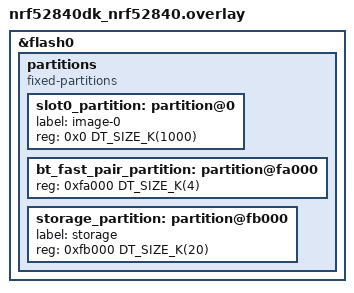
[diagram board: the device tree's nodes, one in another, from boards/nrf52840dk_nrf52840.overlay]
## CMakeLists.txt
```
#
# Copyright (c) 2022 Nordic Semiconductor
#
# SPDX-License-Identifier: LicenseRef-Nordic-5-Clause
#
cmake_minimum_required(VERSION 3.20.0)

find_package(Zephyr REQUIRED HINTS $ENV{ZEPHYR_BASE})
project(input_device)

# NORDIC SDK APP START
target_sources(app PRIVATE
  src/main.c
  src/bt_adv_helper.c
  src/hids_helper.c
  src/bt_le_adv_prov_uuid16.c
  src/battery_module.c
)

target_include_directories(app PRIVATE include)
# NORDIC SDK APP END
```

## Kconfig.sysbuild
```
#
# Copyright (c) 2023-2025 Nordic Semiconductor
#
# SPDX-License-Identifier: LicenseRef-Nordic-5-Clause
#

config BT_FAST_PAIR_MODEL_ID
	default 0x2A410B

# The Anti-Spoofing Private Key is confidential and must be handled securely.
# The following key is only used for demonstration purposes and must not be used in production.
config BT_FAST_PAIR_ANTI_SPOOFING_PRIVATE_KEY
	default "Unoh+nycK/ZJ7k3dHsdcNpiP1SfOy0P/Lx5XixyYois="

source "share/sysbuild/Kconfig"
```

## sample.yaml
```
sample:
  name: Fast Pair input device
  description: Bluetooth Fast Pair Provider sample setup for the input device use
    case
tests:
  sample.bluetooth.fast_pair.input_device:
    build_only: true
    sysbuild: true
    integration_platforms:
      - nrf54l15dk/nrf54l05/cpuapp
      - nrf54lm20dk/nrf54lm20a/cpuapp
      - nrf54lm20dk/nrf54lm20b/cpuapp
      - nrf54ls05dk/nrf54ls05a/cpuapp
      - nrf54lc10dk/nrf54lc10a/cpuapp
    platform_allow:
      - nrf54l15dk/nrf54l05/cpuapp
      - nrf54l15dk/nrf54l10/cpuapp
      - nrf54l15dk/nrf54l15/cpuapp
      - nrf54lm20dk/nrf54lm20a/cpuapp
      - nrf54lm20dk/nrf54lm20b/cpuapp
      - nrf54ls05dk/nrf54ls05a/cpuapp
      - nrf54ls05dk/nrf54ls05b/cpuapp
      - nrf54lc10dk/nrf54lc10a/cpuapp
      - nrf54lc10dk/nrf54lc10a/cpuapp/ns
    tags:
      - bluetooth
      - ci_build
      - sysbuild
      - ci_samples_bluetooth
```

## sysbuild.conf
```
#
# Copyright (c) 2023 Nordic Semiconductor
#
# SPDX-License-Identifier: LicenseRef-Nordic-5-Clause
#

SB_CONFIG_BT=y
SB_CONFIG_BT_FAST_PAIR=y
```

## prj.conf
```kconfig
#
# Copyright (c) 2022-2025 Nordic Semiconductor
#
# SPDX-License-Identifier: LicenseRef-Nordic-5-Clause
#

CONFIG_NCS_SAMPLES_DEFAULTS=y

CONFIG_SYSTEM_WORKQUEUE_PRIORITY=-1
CONFIG_SYSTEM_WORKQUEUE_STACK_SIZE=2048

CONFIG_DK_LIBRARY=y

# Enable settings to store data in non-volatile memory
CONFIG_FLASH=y
CONFIG_FLASH_MAP=y
CONFIG_BT_SETTINGS=y

CONFIG_BT=y
CONFIG_BT_RX_STACK_SIZE=3072
CONFIG_BT_DEVICE_NAME="Nordic_Fast_Pair"
CONFIG_BT_PERIPHERAL=y
CONFIG_BT_PERIPHERAL_PREF_MIN_INT=6
CONFIG_BT_PERIPHERAL_PREF_MAX_INT=6
CONFIG_BT_PERIPHERAL_PREF_LATENCY=99
CONFIG_BT_PERIPHERAL_PREF_TIMEOUT=400
# Appear as a Generic Human Interface Device
CONFIG_BT_DEVICE_APPEARANCE=960

CONFIG_BT_ADV_PROV=y
CONFIG_BT_ADV_PROV_FLAGS=y
CONFIG_BT_ADV_PROV_TX_POWER=y
CONFIG_BT_ADV_PROV_FAST_PAIR=y

CONFIG_BT_ADV_PROV_DEVICE_NAME=y
CONFIG_BT_ADV_PROV_DEVICE_NAME_SD=y
CONFIG_BT_ADV_PROV_GAP_APPEARANCE=y
CONFIG_BT_ADV_PROV_GAP_APPEARANCE_SD=y

# Align the advertised TX power with Fast Pair expectations.
# The value has been tailored for following DKs:
#   * nrf54lm20dk/nrf54lm20a/cpuapp
#   * nrf54lm20dk/nrf54lm20b/cpuapp
CONFIG_BT_ADV_PROV_TX_POWER_CORRECTION_VAL=-15

# Disable automatic initiation of PHY updates.
# Workaround to prevent disconnection with reason 42 (BT_HCI_ERR_DIFF_TRANS_COLLISION).
# Some Android phones reply to the LL_PHY_REQ and at the same time initiate a connection
# update which triggers an invalid procedure collision.
CONFIG_BT_AUTO_PHY_PERIPHERAL_NONE=y

CONFIG_BT_ID_MAX=1
CONFIG_BT_MAX_CONN=1
CONFIG_BT_MAX_PAIRED=8

CONFIG_BT_SMP=y
CONFIG_BT_PRIVACY=y
CONFIG_BT_RPA_TIMEOUT=960
CONFIG_BT_FAST_PAIR=y
CONFIG_BT_FAST_PAIR_USE_CASE_INPUT_DEVICE=y
CONFIG_BT_FAST_PAIR_BN=y

CONFIG_LOG=y
CONFIG_BT_FAST_PAIR_LOG_LEVEL_DBG=y

CONFIG_BT_HIDS=y
CONFIG_BT_HIDS_DEFAULT_PERM_RW_ENCRYPT=y
CONFIG_BT_CONN_CTX=y

# Enable BAS to comply with HID over GATT profile
CONFIG_BT_BAS=y

# Fill DIS characteristic to comply with HID over GATT profile
CONFIG_BT_DIS_MANUF_NAME=y
CONFIG_BT_DIS_MANUF_NAME_STR="NordicSemiconductor"
CONFIG_BT_DIS_PNP=y
CONFIG_BT_DIS_PNP_VID_SRC=2
CONFIG_BT_DIS_PNP_VID=0x1915
CONFIG_BT_DIS_PNP_PID=0xEEED

# Enable code partitioning with DTS
CONFIG_USE_DT_CODE_PARTITION=y
```

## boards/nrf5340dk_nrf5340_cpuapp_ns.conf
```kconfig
#
# Copyright (c) 2025 Nordic Semiconductor ASA
#
# SPDX-License-Identifier: LicenseRef-Nordic-5-Clause
#

# TF-M profile has to be properly configured to be able to run
# the Bluetooth stack which uses PSA crypto API.
# The following configuration is a minimal set of options required.
CONFIG_TFM_PROFILE_TYPE_NOT_SET=y

CONFIG_TFM_PARTITION_PLATFORM=y
CONFIG_TFM_PARTITION_CRYPTO=y
CONFIG_TFM_PARTITION_INTERNAL_TRUSTED_STORAGE=y
CONFIG_TFM_PARTITION_PROTECTED_STORAGE=n
CONFIG_TFM_PARTITION_INITIAL_ATTESTATION=n
```

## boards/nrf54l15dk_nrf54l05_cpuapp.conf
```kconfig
#
# Copyright (c) 2025 Nordic Semiconductor ASA
#
# SPDX-License-Identifier: LicenseRef-Nordic-5-Clause
#

CONFIG_SYSTEM_WORKQUEUE_STACK_SIZE=3584

# Align the advertised TX power with Fast Pair expectations.
CONFIG_BT_ADV_PROV_TX_POWER_CORRECTION_VAL=-11
```

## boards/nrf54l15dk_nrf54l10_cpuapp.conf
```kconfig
#
# Copyright (c) 2025 Nordic Semiconductor ASA
#
# SPDX-License-Identifier: LicenseRef-Nordic-5-Clause
#

CONFIG_SYSTEM_WORKQUEUE_STACK_SIZE=3584
CONFIG_BT_RX_STACK_SIZE=3072

# Align the advertised TX power with Fast Pair expectations.
CONFIG_BT_ADV_PROV_TX_POWER_CORRECTION_VAL=-11
```

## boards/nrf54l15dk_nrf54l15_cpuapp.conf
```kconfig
#
# Copyright (c) 2024-2025 Nordic Semiconductor ASA
#
# SPDX-License-Identifier: LicenseRef-Nordic-5-Clause
#

CONFIG_SYSTEM_WORKQUEUE_STACK_SIZE=3584

# Align the advertised TX power with Fast Pair expectations.
CONFIG_BT_ADV_PROV_TX_POWER_CORRECTION_VAL=-11
```

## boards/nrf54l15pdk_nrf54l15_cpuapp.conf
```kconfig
#
# Copyright (c) 2024 Nordic Semiconductor ASA
#
# SPDX-License-Identifier: LicenseRef-Nordic-5-Clause
#

# Align the advertised TX power with Fast Pair expectations.
# The value has been tailored for following targets:
#   * nrf54l15pdk/nrf54l15/cpuapp
CONFIG_BT_ADV_PROV_TX_POWER_CORRECTION_VAL=-17
```

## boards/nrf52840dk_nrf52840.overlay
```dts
/*
 * Copyright (c) 2026 Nordic Semiconductor ASA
 *
 * SPDX-License-Identifier: LicenseRef-Nordic-5-Clause
 */

&flash0 {
	/* Redefine the "partitions" DTS node. */
	/delete-node/ partitions;

	partitions {
		compatible = "fixed-partitions";
		#address-cells = <1>;
		#size-cells = <1>;

		slot0_partition: partition@0 {
			label = "image-0";
			reg = <0x0 DT_SIZE_K(1000)>;
		};

		bt_fast_pair_partition: partition@fa000 {
			reg = <0xfa000 DT_SIZE_K(4)>;
		};

		storage_partition: partition@fb000 {
			label = "storage";
			reg = <0xfb000 DT_SIZE_K(20)>;
		};
	};
};
```

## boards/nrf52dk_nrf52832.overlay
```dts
/*
 * Copyright (c) 2026 Nordic Semiconductor ASA
 *
 * SPDX-License-Identifier: LicenseRef-Nordic-5-Clause
 */

&flash0 {
	/* Redefine the "partitions" DTS node. */
	/delete-node/ partitions;

	partitions {
		ranges;
		#address-cells = <1>;
		#size-cells = <1>;

		slot0_partition: partition@0 {
			compatible = "zephyr,mapped-partition";
			label = "image-0";
			reg = <0x0 DT_SIZE_K(488)>;
		};

		bt_fast_pair_partition: partition@7a000 {
			compatible = "zephyr,mapped-partition";
			reg = <0x7a000 DT_SIZE_K(4)>;
		};

		storage_partition: partition@7b000 {
			compatible = "zephyr,mapped-partition";
			label = "storage";
			reg = <0x7b000 DT_SIZE_K(20)>;
		};
	};
};
```

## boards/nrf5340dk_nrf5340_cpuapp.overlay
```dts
/*
 * Copyright (c) 2026 Nordic Semiconductor ASA
 *
 * SPDX-License-Identifier: LicenseRef-Nordic-5-Clause
 */

&flash0 {
	/* Redefine the "partitions" DTS node. */
	/delete-node/ partitions;

	partitions {
		ranges;
		#address-cells = <1>;
		#size-cells = <1>;

		slot0_partition: partition@0 {
			compatible = "zephyr,mapped-partition";
			label = "image-0";
			reg = <0x0 DT_SIZE_K(1000)>;
		};

		bt_fast_pair_partition: partition@fa000 {
			compatible = "zephyr,mapped-partition";
			reg = <0xfa000 DT_SIZE_K(4)>;
		};

		storage_partition: partition@fb000 {
			compatible = "zephyr,mapped-partition";
			label = "storage";
			reg = <0xfb000 DT_SIZE_K(20)>;
		};
	};
};
```

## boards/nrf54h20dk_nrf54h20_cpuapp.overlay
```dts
/*
 * Copyright (c) 2024 Nordic Semiconductor ASA
 *
 * SPDX-License-Identifier: LicenseRef-Nordic-5-Clause
 */

/* Define the Fast Pair partition. */
&mram1x {
	partitions {
		/* Align the partition size to 4096 B to avoid gaps. */
		bt_fast_pair_partition: partition@1b0000 {
			compatible = "zephyr,mapped-partition";
			reg = <0x1b0000 DT_SIZE_K(4)>;
		};
	};
};
```

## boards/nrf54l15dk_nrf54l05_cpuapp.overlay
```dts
/*
 * Copyright (c) 2026 Nordic Semiconductor ASA
 *
 * SPDX-License-Identifier: LicenseRef-Nordic-5-Clause
 */

&cpuapp_rram {
	/* Redefine the "partitions" DTS node. */
	/delete-node/ partitions;

	partitions {
		ranges;
		#address-cells = <1>;
		#size-cells = <1>;

		slot0_partition: partition@0 {
			compatible = "zephyr,mapped-partition";
			label = "image-0";
			reg = <0x0 DT_SIZE_K(476)>;
		};

		bt_fast_pair_partition: partition@77000 {
			compatible = "zephyr,mapped-partition";
			reg = <0x77000 DT_SIZE_K(4)>;
		};

		storage_partition: partition@78000 {
			compatible = "zephyr,mapped-partition";
			label = "storage";
			reg = <0x78000 DT_SIZE_K(20)>;
		};
	};
};
```

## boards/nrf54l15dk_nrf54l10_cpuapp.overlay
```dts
/*
 * Copyright (c) 2026 Nordic Semiconductor ASA
 *
 * SPDX-License-Identifier: LicenseRef-Nordic-5-Clause
 */

&cpuapp_rram {
	/* Redefine the "partitions" DTS node. */
	/delete-node/ partitions;

	partitions {
		ranges;
		#address-cells = <1>;
		#size-cells = <1>;

		slot0_partition: partition@0 {
			compatible = "zephyr,mapped-partition";
			label = "image-0";
			reg = <0x0 DT_SIZE_K(988)>;
		};

		bt_fast_pair_partition: partition@f7000 {
			compatible = "zephyr,mapped-partition";
			reg = <0xf7000 DT_SIZE_K(4)>;
		};

		storage_partition: partition@f8000 {
			compatible = "zephyr,mapped-partition";
			label = "storage";
			reg = <0xf8000 DT_SIZE_K(20)>;
		};
	};
};
```

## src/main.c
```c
/*
 * Copyright (c) 2022-2026 Nordic Semiconductor ASA
 *
 * SPDX-License-Identifier: LicenseRef-Nordic-5-Clause
 */

#include <zephyr/kernel.h>
#include <zephyr/sys/__assert.h>
#include <zephyr/bluetooth/bluetooth.h>
#include <zephyr/bluetooth/conn.h>
#include <zephyr/bluetooth/hci.h>
#include <zephyr/settings/settings.h>
#include <bluetooth/fast_pair/fast_pair.h>
#include <bluetooth/adv_prov/fast_pair.h>

#include <dk_buttons_and_leds.h>

#include <zephyr/logging/log.h>
LOG_MODULE_REGISTER(fp_sample, LOG_LEVEL_INF);

#include "bt_adv_helper.h"
#include "hids_helper.h"
#include "battery_module.h"

#define RUN_STATUS_LED						DK_LED1
#define CON_STATUS_LED						DK_LED2
#define FP_ADV_MODE_STATUS_LED					DK_LED3

#define FP_ADV_MODE_BUTTON_MASK					DK_BTN1_MSK
#define VOLUME_UP_BUTTON_MASK					DK_BTN2_MSK
#define BOND_REMOVE_BUTTON_MASK					DK_BTN3_MSK
#define VOLUME_DOWN_BUTTON_MASK					DK_BTN4_MSK

#define RUN_LED_BLINK_INTERVAL_MS				1000
#define FP_ADV_MODE_SHOW_UI_INDICATION_LED_BLINK_INTERVAL_MS	500
#define FP_ADV_MODE_HIDE_UI_INDICATION_LED_BLINK_INTERVAL_MS	1500

#define FP_DISC_ADV_TIMEOUT_MINUTES				(10)

#define INIT_SEM_TIMEOUT_SECONDS				(60)

static enum bt_fast_pair_adv_mode fp_adv_mode = BT_FAST_PAIR_ADV_MODE_DISC;
static bool show_ui_pairing = true;
static bool new_adv_session = true;
static struct bt_conn *peer;

static struct k_work bt_adv_restart;
static struct k_work_delayable fp_adv_mode_status_led_handle;
static struct k_work_delayable fp_disc_adv_timeout;

static void init_work_handle(struct k_work *w);

static K_SEM_DEFINE(init_work_sem, 0, 1);
static K_WORK_DEFINE(init_work, init_work_handle);


static void bond_cnt_cb(const struct bt_bond_info *info, void *user_data)
{
	size_t *cnt = user_data;

	(*cnt)++;
}

static size_t bond_cnt(void)
{
	size_t cnt = 0;

	bt_foreach_bond(BT_ID_DEFAULT, bond_cnt_cb, &cnt);

	return cnt;
}

static bool can_pair(void)
{
	return (bond_cnt() < CONFIG_BT_MAX_PAIRED);
}

static void advertising_stop(void)
{
	int ret = k_work_cancel_delayable(&fp_disc_adv_timeout);

	__ASSERT_NO_MSG((ret & ~(K_WORK_CANCELING)) == 0);

	ret = bt_adv_helper_adv_stop();
	if (ret) {
		LOG_ERR("Failed to stop advertising (err %d)", ret);
	}
}

static void advertising_start(void)
{
	int err;
	int ret;

	ARG_UNUSED(ret);

	if (!can_pair()) {
		if ((fp_adv_mode == BT_FAST_PAIR_ADV_MODE_DISC) || show_ui_pairing) {
			LOG_INF("Automatically switching to not discoverable advertising, hide UI "
				"indication, because all bond slots are taken");
			fp_adv_mode = BT_FAST_PAIR_ADV_MODE_NOT_DISC;
			show_ui_pairing = false;

			ret = k_work_reschedule(&fp_adv_mode_status_led_handle, K_NO_WAIT);
			__ASSERT_NO_MSG((ret == 0) || (ret == 1));
		}
	}

	bt_le_adv_prov_fast_pair_show_ui_pairing(show_ui_pairing);

	err = bt_adv_helper_adv_start((fp_adv_mode == BT_FAST_PAIR_ADV_MODE_DISC), new_adv_session);

	new_adv_session = false;

	ret = k_work_cancel_delayable(&fp_disc_adv_timeout);

	/* The advertising_start function may be called from discoverable advertising timeout work
	 * handler. In that case work would initially be in a running state.
	 */
	__ASSERT_NO_MSG((ret & ~(K_WORK_RUNNING | K_WORK_CANCELING)) == 0);

	if ((fp_adv_mode == BT_FAST_PAIR_ADV_MODE_DISC) && !err) {
		ret = k_work_reschedule(&fp_disc_adv_timeout,
					K_MINUTES(FP_DISC_ADV_TIMEOUT_MINUTES));

		__ASSERT_NO_MSG(ret == 1);
	}

	if (!err) {
		if (fp_adv_mode == BT_FAST_PAIR_ADV_MODE_DISC) {
			LOG_INF("Discoverable advertising started");
		} else {
			LOG_INF("Not discoverable advertising started, %s UI indication enabled",
				show_ui_pairing ? "show" : "hide");
		}
	} else {
		LOG_ERR("Advertising failed to start (err %d)", err);
	}
}

static void bt_adv_restart_fn(struct k_work *w)
{
	advertising_start();
}

static void fp_adv_mode_status_led_handle_fn(struct k_work *w)
{
	ARG_UNUSED(w);

	static bool led_on = true;
	int ret;

	ARG_UNUSED(ret);

	switch (fp_adv_mode) {
	case BT_FAST_PAIR_ADV_MODE_DISC:
		dk_set_led_on(FP_ADV_MODE_STATUS_LED);
		break;

	case BT_FAST_PAIR_ADV_MODE_NOT_DISC:
		dk_set_led(FP_ADV_MODE_STATUS_LED, led_on);
		led_on = !led_on;
		ret = k_work_reschedule(&fp_adv_mode_status_led_handle, show_ui_pairing ?
				K_MSEC(FP_ADV_MODE_SHOW_UI_INDICATION_LED_BLINK_INTERVAL_MS) :
				K_MSEC(FP_ADV_MODE_HIDE_UI_INDICATION_LED_BLINK_INTERVAL_MS));
		__ASSERT_NO_MSG(ret == 1);
		break;

	default:
		__ASSERT_NO_MSG(false);
	}
}

static void fp_disc_adv_timeout_fn(struct k_work *w)
{
	ARG_UNUSED(w);

	__ASSERT_NO_MSG(fp_adv_mode == BT_FAST_PAIR_ADV_MODE_DISC);
	__ASSERT_NO_MSG(!peer);

	LOG_INF("Discoverable advertising timed out");

	/* Switch to not discoverable advertising showing UI indication. */
	fp_adv_mode = BT_FAST_PAIR_ADV_MODE_NOT_DISC;
	show_ui_pairing = true;

	fp_adv_mode_status_led_handle_fn(NULL);
	advertising_start();
}

static void connected(struct bt_conn *conn, uint8_t err)
{
	int ret = k_work_cancel_delayable(&fp_disc_adv_timeout);

	__ASSERT_NO_MSG(ret == 0);
	ret = k_work_cancel(&bt_adv_restart);
	__ASSERT_NO_MSG(ret == 0);
	ARG_UNUSED(ret);

	/* Multiple simultaneous connections are not supported by the sample. */
	__ASSERT_NO_MSG(!peer);

	if (err) {
		LOG_WRN("Connection failed, err 0x%02x %s", err, bt_hci_err_to_str(err));
		ret = k_work_submit(&bt_adv_restart);
		__ASSERT_NO_MSG(ret == 1);
		return;
	}

	LOG_INF("Connected");

	dk_set_led_on(CON_STATUS_LED);
	peer = conn;
}

static void disconnected(struct bt_conn *conn, uint8_t reason)
{
	LOG_INF("Disconnected, reason 0x%02x %s", reason, bt_hci_err_to_str(reason));

	dk_set_led_off(CON_STATUS_LED);
	peer = NULL;

	int ret = k_work_submit(&bt_adv_restart);

	__ASSERT_NO_MSG(ret == 1);
	ARG_UNUSED(ret);

	new_adv_session = true;
}

static void security_changed(struct bt_conn *conn, bt_security_t level, enum bt_security_err err)
{
	char addr[BT_ADDR_LE_STR_LEN];

	bt_addr_le_to_str(bt_conn_get_dst(conn), addr, sizeof(addr));

	if (!err) {
		LOG_INF("Security changed: %s level %u", addr, level);
	} else {
		LOG_WRN("Security failed: %s level %u err %d %s", addr, level, err,
			bt_security_err_to_str(err));
	}
}

BT_CONN_CB_DEFINE(conn_callbacks) = {
	.connected        = connected,
	.disconnected     = disconnected,
	.security_changed = security_changed,
};

static void pairing_complete(struct bt_conn *conn, bool bonded)
{
	if (bonded && (fp_adv_mode == BT_FAST_PAIR_ADV_MODE_DISC)) {
		fp_adv_mode = BT_FAST_PAIR_ADV_MODE_NOT_DISC;
		show_ui_pairing = true;
		int ret = k_work_reschedule(&fp_adv_mode_status_led_handle, K_NO_WAIT);

		__ASSERT_NO_MSG((ret == 0) || (ret == 1));
		ARG_UNUSED(ret);
	}
}

static enum bt_security_err pairing_accept(struct bt_conn *conn,
					   const struct bt_conn_pairing_feat *const feat)
{
	ARG_UNUSED(conn);
	ARG_UNUSED(feat);

	enum bt_security_err ret;

	if (fp_adv_mode != BT_FAST_PAIR_ADV_MODE_DISC) {
		LOG_WRN("Normal Bluetooth pairing not allowed outside of pairing mode");
		ret = BT_SECURITY_ERR_PAIR_NOT_ALLOWED;
	} else {
		LOG_INF("Accept normal Bluetooth pairing");
		ret = BT_SECURITY_ERR_SUCCESS;
	}

	return ret;
}

static const char *volume_change_to_str(enum hids_helper_volume_change volume_change)
{
	const char *res = NULL;

	switch (volume_change) {
	case HIDS_HELPER_VOLUME_CHANGE_DOWN:
		res = "Decrease";
		break;

	case HIDS_HELPER_VOLUME_CHANGE_NONE:
		break;

	case HIDS_HELPER_VOLUME_CHANGE_UP:
		res = "Increase";
		break;

	default:
		/* Should not happen. */
		__ASSERT_NO_MSG(false);
		break;
	}

	return res;
}

static void hid_volume_control_send(enum hids_helper_volume_change volume_change)
{
	const char *operation_str = volume_change_to_str(volume_change);
	int err = hids_helper_volume_ctrl(volume_change);

	if (!err) {
		if (operation_str) {
			LOG_INF("%s audio volume", operation_str);
		}
	} else {
		/* HID host not connected or not subscribed. Silently drop HID data. */
	}
}

static void volume_control_btn_handle(uint32_t button_state, uint32_t has_changed)
{
	static enum hids_helper_volume_change volume_change = HIDS_HELPER_VOLUME_CHANGE_NONE;
	enum hids_helper_volume_change new_volume_change = volume_change;

	if (has_changed & VOLUME_UP_BUTTON_MASK) {
		if (button_state & VOLUME_UP_BUTTON_MASK) {
			new_volume_change = HIDS_HELPER_VOLUME_CHANGE_UP;
		} else if (volume_change == HIDS_HELPER_VOLUME_CHANGE_UP) {
			new_volume_change = HIDS_HELPER_VOLUME_CHANGE_NONE;
		}
	}

	if (has_changed & VOLUME_DOWN_BUTTON_MASK) {
		if (button_state & VOLUME_DOWN_BUTTON_MASK) {
			new_volume_change = HIDS_HELPER_VOLUME_CHANGE_DOWN;
		} else if (volume_change == HIDS_HELPER_VOLUME_CHANGE_DOWN) {
			new_volume_change = HIDS_HELPER_VOLUME_CHANGE_NONE;
		}
	}

	if (volume_change != new_volume_change) {
		volume_change = new_volume_change;
		hid_volume_control_send(volume_change);
	}
}

static void fp_adv_mode_btn_handle(uint32_t button_state, uint32_t has_changed)
{
	uint32_t button_pressed = button_state & has_changed;

	if (button_pressed & FP_ADV_MODE_BUTTON_MASK) {
		if (fp_adv_mode == BT_FAST_PAIR_ADV_MODE_DISC) {
			fp_adv_mode = BT_FAST_PAIR_ADV_MODE_NOT_DISC;
			show_ui_pairing = true;
		} else {
			if (show_ui_pairing) {
				show_ui_pairing = false;
			} else {
				fp_adv_mode = BT_FAST_PAIR_ADV_MODE_DISC;
			}
		}

		if (!peer) {
			new_adv_session = true;
			advertising_start();
		}

		int ret = k_work_reschedule(&fp_adv_mode_status_led_handle, K_NO_WAIT);

		__ASSERT_NO_MSG((ret == 0) || (ret == 1));
		ARG_UNUSED(ret);
	}
}

static void bond_remove_btn_handle(uint32_t button_state, uint32_t has_changed)
{
	uint32_t button_pressed = button_state & has_changed;

	if (button_pressed & BOND_REMOVE_BUTTON_MASK) {
		advertising_stop();

		int err = bt_unpair(BT_ID_DEFAULT, NULL);

		if (err) {
			LOG_ERR("Cannot remove bonds (err %d)", err);
		} else {
			LOG_INF("Bonds removed");
		}

		if (!peer) {
			new_adv_session = true;
			advertising_start();
		}
	}
}

static void button_changed(uint32_t button_state, uint32_t has_changed)
{
	__ASSERT_NO_MSG(!k_is_in_isr());
	__ASSERT_NO_MSG(!k_is_preempt_thread());

	fp_adv_mode_btn_handle(button_state, has_changed);
	volume_control_btn_handle(button_state, has_changed);
	bond_remove_btn_handle(button_state, has_changed);
}

static void fp_account_key_written(struct bt_conn *conn)
{
	LOG_INF("Fast Pair Account Key has been written");
}

static void init_work_handle(struct k_work *w)
{
	int err;
	static const struct bt_conn_auth_cb conn_auth_callbacks = {
		.pairing_accept = pairing_accept,
	};
	static struct bt_conn_auth_info_cb auth_info_cb = {
		.pairing_complete = pairing_complete
	};
	static struct bt_fast_pair_info_cb fp_info_callbacks = {
		.account_key_written = fp_account_key_written,
	};

	/* It is assumed that this function executes in the cooperative thread context. */
	__ASSERT_NO_MSG(!k_is_preempt_thread());
	__ASSERT_NO_MSG(!k_is_in_isr());

	err = bt_conn_auth_cb_register(&conn_auth_callbacks);
	if (err) {
		LOG_ERR("Registering authentication callbacks failed (err %d)", err);
		return;
	}

	err = bt_conn_auth_info_cb_register(&auth_info_cb);
	if (err) {
		LOG_ERR("Registering authentication info callbacks failed (err %d)", err);
		return;
	}

	err = bt_fast_pair_info_cb_register(&fp_info_callbacks);
	if (err) {
		LOG_ERR("Registering Fast Pair info callbacks failed (err %d)", err);
		return;
	}

	err = hids_helper_init();
	if (err) {
		LOG_ERR("HIDS init failed (err %d)", err);
		return;
	}

	err = bt_enable(NULL);
	if (err) {
		LOG_ERR("Bluetooth init failed (err %d)", err);
		return;
	}

	LOG_INF("Bluetooth initialized");

	err = settings_load();
	if (err) {
		LOG_ERR("Settings load failed (err: %d)", err);
		return;
	}

	LOG_INF("Settings loaded");

	err = bt_fast_pair_enable();
	if (err) {
		LOG_ERR("Fast Pair enable failed (err: %d)", err);
		return;
	}

	err = dk_leds_init();
	if (err) {
		LOG_ERR("LEDs init failed (err %d)", err);
		return;
	}

	err = battery_module_init();
	if (err) {
		LOG_ERR("Battery module init failed (err %d)", err);
		return;
	}

	err = bt_le_adv_prov_fast_pair_set_battery_mode(BT_FAST_PAIR_ADV_BATTERY_MODE_SHOW_UI_IND);
	if (err) {
		LOG_ERR("Setting advertising battery mode failed (err %d)", err);
		return;
	}

	k_work_init(&bt_adv_restart, bt_adv_restart_fn);
	k_work_init_delayable(&fp_adv_mode_status_led_handle, fp_adv_mode_status_led_handle_fn);
	k_work_init_delayable(&fp_disc_adv_timeout, fp_disc_adv_timeout_fn);

	int ret = k_work_schedule(&fp_adv_mode_status_led_handle, K_NO_WAIT);

	__ASSERT_NO_MSG(ret == 1);
	ret = k_work_submit(&bt_adv_restart);
	__ASSERT_NO_MSG(ret == 1);
	ARG_UNUSED(ret);

	err = dk_buttons_init(button_changed);
	if (err) {
		LOG_ERR("Buttons init failed (err %d)", err);
		return;
	}

	k_sem_give(&init_work_sem);
}

int main(void)
{
	bool run_led_on = true;
	int err;

	LOG_INF("Starting Bluetooth Fast Pair input device sample");

	/* Switch to the cooperative thread context before interaction
	 * with the Fast Pair API.
	 */
	(void) k_work_submit(&init_work);
	err = k_sem_take(&init_work_sem, K_SECONDS(INIT_SEM_TIMEOUT_SECONDS));
	if (err) {
		k_panic();
		return 0;
	}

	LOG_INF("Sample has started");

	for (;;) {
		dk_set_led(RUN_STATUS_LED, run_led_on);
		run_led_on = !run_led_on;
		k_sleep(K_MSEC(RUN_LED_BLINK_INTERVAL_MS));
	}
}
```

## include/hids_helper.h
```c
/*
 * Copyright (c) 2022 Nordic Semiconductor ASA
 *
 * SPDX-License-Identifier: LicenseRef-Nordic-5-Clause
 */

#ifndef HIDS_HELPER_H_
#define HIDS_HELPER_H_

/**
 * @defgroup fast_pair_sample_hids_helper Fast Pair sample HIDS API
 * @brief Fast Pair sample HIDS API
 *
 * @{
 */

#ifdef __cplusplus
extern "C" {
#endif

/** @brief Audio volume change. */
enum hids_helper_volume_change {
	/** Decrease audio volume. */
	HIDS_HELPER_VOLUME_CHANGE_DOWN,

	/** Keep constant audio volume. */
	HIDS_HELPER_VOLUME_CHANGE_NONE,

	/** Increase audio volume. */
	HIDS_HELPER_VOLUME_CHANGE_UP,
};

/** Initialize HIDS
 *
 * Only one consumer control HID report is supported by the report map. The HID report is used to
 * control the audio volume.
 *
 * @return 0 if the operation was successful. Otherwise, a (negative) error code is returned.
 */
int hids_helper_init(void);

/** Send HID report to control audio volume
 *
 * @param[in] volume_change Enumerator indicating if audio volume should be increased, decreased or
 *                          kept constant.
 *
 * @return 0 if the operation was successful. Otherwise, a (negative) error code is returned.
 */
int hids_helper_volume_ctrl(enum hids_helper_volume_change volume_change);

#ifdef __cplusplus
}
#endif

/**
 * @}
 */

#endif /* HIDS_HELPER_H_ */
```

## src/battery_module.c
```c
/*
 * Copyright (c) 2022-2026 Nordic Semiconductor ASA
 *
 * SPDX-License-Identifier: LicenseRef-Nordic-5-Clause
 */

#include <bluetooth/fast_pair/fast_pair.h>

#include <zephyr/logging/log.h>
LOG_MODULE_DECLARE(fp_sample, LOG_LEVEL_INF);

#include "battery_module.h"

int battery_module_init(void)
{
	static const struct bt_fast_pair_battery fp_batteries[BT_FAST_PAIR_BATTERY_COMP_COUNT] = {
		[BT_FAST_PAIR_BATTERY_COMP_LEFT_BUD]  = { .charging = true, .level = 67},
		[BT_FAST_PAIR_BATTERY_COMP_RIGHT_BUD] = { .charging = false, .level = 100},
		[BT_FAST_PAIR_BATTERY_COMP_BUD_CASE]  = { .charging = false, .level = 1},
	};
	int err;

	for (size_t i = 0; i < BT_FAST_PAIR_BATTERY_COMP_COUNT; i++) {
		err = bt_fast_pair_battery_set(i, fp_batteries[i]);
		if (err) {
			LOG_ERR("Unable to set battery value (err %d, idx %zu)", err, i);
			return err;
		}
	}

	return 0;
}
```

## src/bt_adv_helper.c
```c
/*
 * Copyright (c) 2022-2023 Nordic Semiconductor ASA
 *
 * SPDX-License-Identifier: LicenseRef-Nordic-5-Clause
 */

#include <zephyr/random/random.h>
#include <zephyr/sys/clock.h>
#include <zephyr/sys/__assert.h>

#include <zephyr/bluetooth/bluetooth.h>
#include <zephyr/bluetooth/conn.h>
#include <bluetooth/adv_prov.h>

#include <zephyr/logging/log.h>
LOG_MODULE_DECLARE(fp_sample, LOG_LEVEL_INF);

#include "bt_adv_helper.h"

/* According to Fast Pair specification RPA rotation must be synchronized with generating new salt
 * for Acount Key Filter advertising data. The RPA rotation must occur at least every 15 minutes
 * while the device is actively advertising in Fast Pair not discoverable mode. The value of this
 * timeout must be lower than CONFIG_BT_RPA_TIMEOUT to ensure that RPA rotation will always trigger
 * update of Account Key Filter advertising data.
 */
#define RPA_TIMEOUT_NOT_DISC		(13 * SEC_PER_MIN)
#define RPA_TIMEOUT_OFFSET_MAX		(2 * SEC_PER_MIN)
#define RPA_TIMEOUT_FAST_PAIR_MAX	(15 * SEC_PER_MIN)

BUILD_ASSERT(RPA_TIMEOUT_FAST_PAIR_MAX < CONFIG_BT_RPA_TIMEOUT);

static bool adv_helper_pairing_mode;
static bool adv_helper_new_adv_session;

static void rpa_rotate_fn(struct k_work *w);
static K_WORK_DELAYABLE_DEFINE(rpa_rotate, rpa_rotate_fn);


static void connected(struct bt_conn *conn, uint8_t err)
{
	if (!err) {
		int ret = k_work_cancel_delayable(&rpa_rotate);

		__ASSERT_NO_MSG(ret == 0);
		ARG_UNUSED(ret);
	}
}

BT_CONN_CB_DEFINE(conn_callbacks) = {
	.connected        = connected,
};

static int adv_start_internal(void)
{
	struct bt_le_oob oob;
	int err = bt_le_adv_stop();

	if (err) {
		LOG_ERR("Cannot stop advertising (err: %d)", err);
		return err;
	}

	/* Generate new Resolvable Private Address (RPA). */
	err = bt_le_oob_get_local(BT_ID_DEFAULT, &oob);
	if (err) {
		LOG_ERR("Cannot trigger RPA rotation (err: %d)", err);
		return err;
	}

	size_t ad_len = bt_le_adv_prov_get_ad_prov_cnt();
	size_t sd_len = bt_le_adv_prov_get_sd_prov_cnt();
	struct bt_data ad[ad_len];
	struct bt_data sd[sd_len];

	struct bt_le_adv_prov_adv_state state;
	struct bt_le_adv_prov_feedback fb;

	state.pairing_mode = adv_helper_pairing_mode;
	state.in_grace_period = false;
	state.rpa_rotated = true;
	state.new_adv_session = adv_helper_new_adv_session;
	state.adv_handle = 0;

	adv_helper_new_adv_session = false;

	err = bt_le_adv_prov_get_ad(ad, &ad_len, &state, &fb);
	if (err) {
		LOG_ERR("Cannot get advertising data (err: %d)", err);
		return err;
	}

	err = bt_le_adv_prov_get_sd(sd, &sd_len, &state, &fb);
	if (err) {
		LOG_ERR("Cannot get scan response data (err: %d)", err);
		return err;
	}

	/* According to Fast Pair specification, the advertising interval should be no longer than
	 * 100 ms when discoverable and no longer than 250 ms when not discoverable.
	 */
	static const struct bt_le_adv_param adv_param = {
		.id = BT_ID_DEFAULT,
		.options = BT_LE_ADV_OPT_CONN,
		.interval_min = BT_GAP_ADV_FAST_INT_MIN_1,
		.interval_max = BT_GAP_ADV_FAST_INT_MAX_1,
		.peer = NULL,
	};

	err = bt_le_adv_start(&adv_param, ad, ad_len, sd, sd_len);

	if ((!err) && (!adv_helper_pairing_mode)) {
		unsigned int rpa_timeout_ms = RPA_TIMEOUT_NOT_DISC * MSEC_PER_SEC;
		int8_t rand;

		err = sys_csrand_get(&rand, sizeof(rand));
		if (!err) {
			rpa_timeout_ms += ((int)(RPA_TIMEOUT_OFFSET_MAX * MSEC_PER_SEC)) *
					  rand / INT8_MAX;
		} else {
			LOG_WRN("Cannot get random RPA timeout (err: %d). Used fixed value", err);
		}

		__ASSERT_NO_MSG(rpa_timeout_ms <= RPA_TIMEOUT_FAST_PAIR_MAX * MSEC_PER_SEC);
		int ret = k_work_schedule(&rpa_rotate, K_MSEC(rpa_timeout_ms));

		__ASSERT_NO_MSG(ret == 1);
		ARG_UNUSED(ret);
	}

	return err;

}

static void rpa_rotate_fn(struct k_work *w)
{
	(void)adv_start_internal();
}

int bt_adv_helper_adv_start(bool pairing_mode, bool new_adv_session)
{
	int ret = k_work_cancel_delayable(&rpa_rotate);

	__ASSERT_NO_MSG(ret == 0);
	ARG_UNUSED(ret);

	adv_helper_pairing_mode = pairing_mode;
	adv_helper_new_adv_session = new_adv_session;

	LOG_INF("Looking for a new peer: %s", pairing_mode ? "yes" : "no");

	return adv_start_internal();
}

int bt_adv_helper_adv_stop(void)
{
	int ret = k_work_cancel_delayable(&rpa_rotate);

	__ASSERT_NO_MSG(ret == 0);
	ARG_UNUSED(ret);

	return bt_le_adv_stop();
}
```

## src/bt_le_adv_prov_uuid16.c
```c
/*
 * Copyright (c) 2022 Nordic Semiconductor ASA
 *
 * SPDX-License-Identifier: LicenseRef-Nordic-5-Clause
 */

#include <zephyr/bluetooth/uuid.h>
#include <bluetooth/adv_prov.h>


static int get_data(struct bt_data *ad, const struct bt_le_adv_prov_adv_state *state,
		    struct bt_le_adv_prov_feedback *fb)
{
	ARG_UNUSED(fb);

	if (!state->pairing_mode) {
		return -ENOENT;
	}

	static const uint8_t data[] = {
		BT_UUID_16_ENCODE(BT_UUID_HIDS_VAL),
		BT_UUID_16_ENCODE(BT_UUID_BAS_VAL),
	};

	ad->type = BT_DATA_UUID16_ALL;
	ad->data_len = sizeof(data);
	ad->data = data;

	return 0;
}

BT_LE_ADV_PROV_AD_PROVIDER_REGISTER(uuid16_all, get_data);
```
